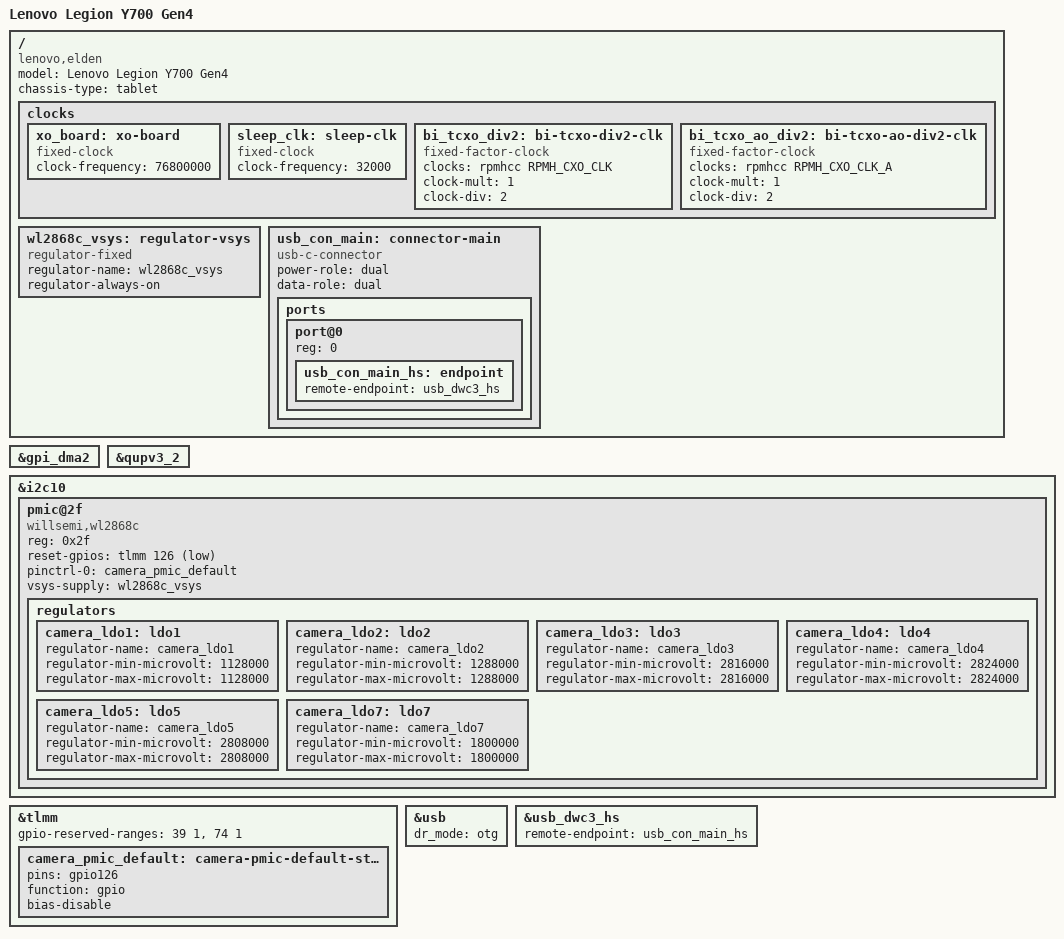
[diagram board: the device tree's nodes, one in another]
// SPDX-License-Identifier: BSD-3-Clause
/*
 * Copyright (c) 2026, Qianhui Xu <xiaqinghuan@mail.ustc.edu.cn>
 */

/dts-v1/;

#include <dt-bindings/gpio/gpio.h>
#include "sm8750.dtsi"

/ {
	model = "Lenovo Legion Y700 Gen4";
	compatible = "lenovo,elden", "qcom,sm8750";
	chassis-type = "tablet";

	clocks {
		xo_board: xo-board {
			compatible = "fixed-clock";
			clock-frequency = <76800000>;
			#clock-cells = <0>;
		};

		sleep_clk: sleep-clk {
			compatible = "fixed-clock";
			clock-frequency = <32000>;
			#clock-cells = <0>;
		};

		bi_tcxo_div2: bi-tcxo-div2-clk {
			compatible = "fixed-factor-clock";
			#clock-cells = <0>;

			clocks = <&rpmhcc RPMH_CXO_CLK>;
			clock-mult = <1>;
			clock-div = <2>;
		};

		bi_tcxo_ao_div2: bi-tcxo-ao-div2-clk {
			compatible = "fixed-factor-clock";
			#clock-cells = <0>;

			clocks = <&rpmhcc RPMH_CXO_CLK_A>;
			clock-mult = <1>;
			clock-div = <2>;
		};
	};

	/*
	 * VSYS of the camera PMIC is the always-on system rail of the tablet.
	 * The SPMI PMICs that generate it are not described yet, so it is
	 * modelled as a fixed regulator without a voltage constraint.
	 */
	wl2868c_vsys: regulator-vsys {
		compatible = "regulator-fixed";
		regulator-name = "wl2868c_vsys";
		regulator-always-on;
	};

	/* Long-edge Type-C receptacle (USB data / debug). */
	usb_con_main: connector-main {
		compatible = "usb-c-connector";
		power-role = "dual";
		data-role = "dual";

		ports {
			#address-cells = <1>;
			#size-cells = <0>;

			port@0 {
				reg = <0>;

				usb_con_main_hs: endpoint {
					remote-endpoint = <&usb_dwc3_hs>;
				};
			};
		};
	};
};

&gpi_dma2 {
	status = "okay";
};

&qupv3_2 {
	status = "okay";
};

&i2c10 {
	status = "okay";

	pmic@2f {
		compatible = "willsemi,wl2868c";
		reg = <0x2f>;
		reset-gpios = <&tlmm 126 GPIO_ACTIVE_LOW>;
		pinctrl-names = "default";
		pinctrl-0 = <&camera_pmic_default>;
		vsys-supply = <&wl2868c_vsys>;

		regulators {
			/* Voltages include the offsets programmed by stock firmware. */
			camera_ldo1: ldo1 {
				regulator-name = "camera_ldo1";
				regulator-min-microvolt = <1128000>;
				regulator-max-microvolt = <1128000>;
			};

			camera_ldo2: ldo2 {
				regulator-name = "camera_ldo2";
				regulator-min-microvolt = <1288000>;
				regulator-max-microvolt = <1288000>;
			};

			camera_ldo3: ldo3 {
				regulator-name = "camera_ldo3";
				regulator-min-microvolt = <2816000>;
				regulator-max-microvolt = <2816000>;
			};

			camera_ldo4: ldo4 {
				regulator-name = "camera_ldo4";
				regulator-min-microvolt = <2824000>;
				regulator-max-microvolt = <2824000>;
			};

			camera_ldo5: ldo5 {
				regulator-name = "camera_ldo5";
				regulator-min-microvolt = <2808000>;
				regulator-max-microvolt = <2808000>;
			};

			/* LDO6 is not wired out on this board. */
			camera_ldo7: ldo7 {
				regulator-name = "camera_ldo7";
				regulator-min-microvolt = <1800000>;
				regulator-max-microvolt = <1800000>;
			};
		};
	};
};

&tlmm {
	gpio-reserved-ranges = <39 1>, <74 1>;

	camera_pmic_default: camera-pmic-default-state {
		pins = "gpio126";
		function = "gpio";
		bias-disable;
	};
};

&usb {
	dr_mode = "otg";
	status = "okay";
};

&usb_dwc3_hs {
	remote-endpoint = <&usb_con_main_hs>;
};
